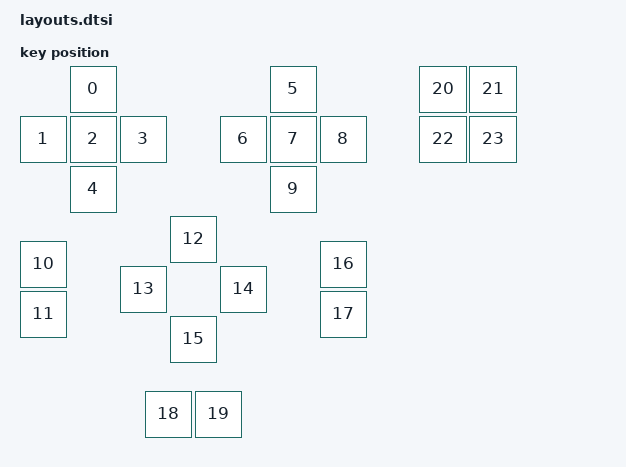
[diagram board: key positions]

#include <physical_layouts.dtsi>
/ {
    physical_layout0: physical_layout0 {
        compatible = "zmk,physical-layout";
        display-name = "Layout";
        keys
=<&key_physical_attrs 100 100 100 0 0 0 0>
,<&key_physical_attrs 100 100 0 100 0 0 0>
,<&key_physical_attrs 100 100 100 100 0 0 0>
,<&key_physical_attrs 100 100 200 100 0 0 0>
,<&key_physical_attrs 100 100 100 200 0 0 0>

,<&key_physical_attrs 100 100 500 0 0 0 0>
,<&key_physical_attrs 100 100 400 100 0 0 0>
,<&key_physical_attrs 100 100 500 100 0 0 0>
,<&key_physical_attrs 100 100 600 100 0 0 0>
,<&key_physical_attrs 100 100 500 200 0 0 0>

,<&key_physical_attrs 100 100 0 350 0 0 0>
,<&key_physical_attrs 100 100 0 450 0 0 0>

,<&key_physical_attrs 100 100 300 300 0 0 0>
,<&key_physical_attrs 100 100 200 400 0 0 0>
,<&key_physical_attrs 100 100 400 400 0 0 0>
,<&key_physical_attrs 100 100 300 500 0 0 0>

,<&key_physical_attrs 100 100 600 350 0 0 0>
,<&key_physical_attrs 100 100 600 450 0 0 0>

,<&key_physical_attrs 100 100 250 650 0 0 0>
,<&key_physical_attrs 100 100 350 650 0 0 0>

,<&key_physical_attrs 100 100 800 0 0 0 0>
,<&key_physical_attrs 100 100 900 0 0 0 0>
,<&key_physical_attrs 100 100 800 100 0 0 0>
,<&key_physical_attrs 100 100 900 100 0 0 0>
            ;
    };
};
